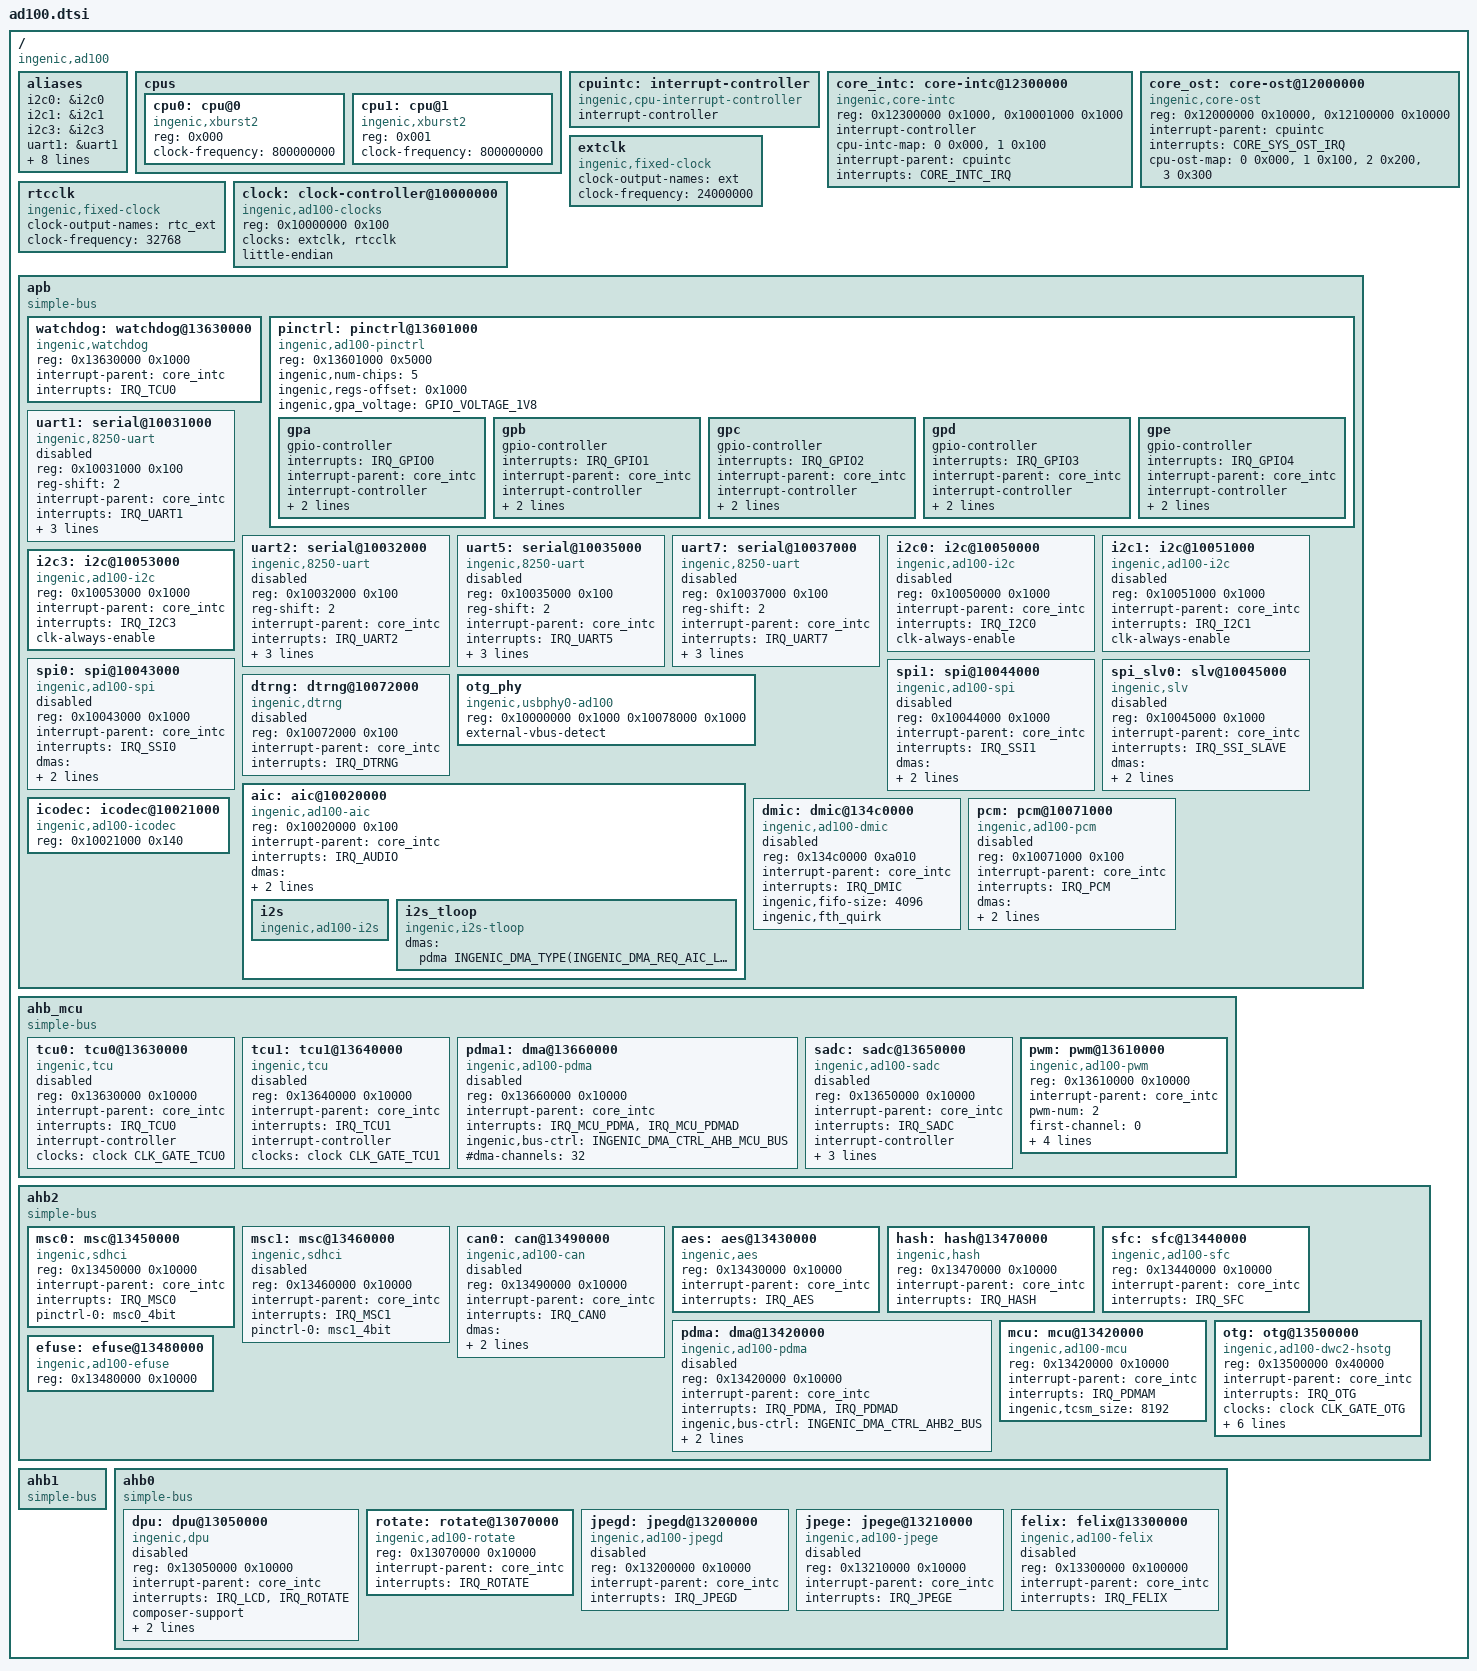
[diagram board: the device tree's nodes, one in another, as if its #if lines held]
#include <dt-bindings/interrupt-controller/ad100-irq.h>
#include <dt-bindings/gpio/ingenic-gpio.h>
#include <dt-bindings/clock/ingenic-tcu.h>
#include <dt-bindings/clock/ingenic-ad100.h>
#include <dt-bindings/sound/ingenic-baic.h>
#include <dt-bindings/gpio/ingenic-gpio.h>
#include <dt-bindings/dma/ingenic-pdma.h>

/ {
	#address-cells = <1>;
	#size-cells = <1>;
	compatible = "ingenic,ad100";

	aliases: aliases {
		i2c0 = &i2c0;
		i2c1 = &i2c1;
		i2c3 = &i2c3;
		uart1 = &uart1;
		uart2 = &uart2;
		uart5 = &uart5;
		uart7 = &uart7;
		mmc0 = &msc0;
		mmc1 = &msc1;
		spi0 = &spi0;
		spi1 = &spi1;
		can0 = &can0;
	};

	cpus: cpus {
		#address-cells = <1>;
		#size-cells = <0>;

		cpu0: cpu@0 {
			device_type = "cpu";
			compatible = "ingenic,xburst2";
			reg = <0x000>;
			clock-frequency = <800000000>;
		};

		cpu1: cpu@1 {
			device_type = "cpu";
			compatible = "ingenic,xburst2";
			reg = <0x001>;
			clock-frequency = <800000000>;
		};
	};

	cpuintc: interrupt-controller {
		#address-cells = <0>;
		#interrupt-cells = <1>;
		interrupt-controller;
		compatible = "ingenic,cpu-interrupt-controller";

	};

	core_intc: core-intc@12300000 {
		compatible = "ingenic,core-intc";
		reg = <0x12300000 0x1000>,
		    <0x10001000 0x1000>;
		interrupt-controller;
		#interrupt-cells = <1>;
		cpu-intc-map = <0 0x000>,
			           <1 0x100>;

		interrupt-parent = <&cpuintc>;
		interrupts = <CORE_INTC_IRQ>;
		interrupt-names ="intc";
	};

	core_ost: core-ost@12000000 {
		compatible = "ingenic,core-ost";
		reg = <0x12000000 0x10000>, /*Global ost*/
		      <0x12100000 0x10000>; /*Core ost*/
		interrupt-parent = <&cpuintc>;
		interrupt-names = "sys_ost";
		interrupts = <CORE_SYS_OST_IRQ>;
		cpu-ost-map = 	<0 0x000>,
			<1 0x100>,
			<2 0x200>,
			<3 0x300>;
	};

	extclk: extclk {
		compatible = "ingenic,fixed-clock";
		clock-output-names ="ext";
		#clock-cells = <0>;
		clock-frequency  = <24000000>;
	};

	rtcclk: rtcclk {
		compatible = "ingenic,fixed-clock";
		clock-output-names ="rtc_ext";
		#clock-cells = <0>;
		clock-frequency = <32768>;
	};

	clock: clock-controller@10000000 {
		compatible = "ingenic,ad100-clocks";
		reg = <0x10000000 0x100>;
		clocks = <&extclk>, <&rtcclk>;
		clock-names = "ext", "rtc_ext";
		#clock-cells = <1>;
		little-endian;
	};

	apb {
		compatible = "simple-bus";
		#address-cells = <1>;
		#size-cells = <1>;
		ranges = <>;
		watchdog: watchdog@13630000 {
				compatible = "ingenic,watchdog";
				reg = <0x13630000 0x1000>;
				interrupt-parent = <&core_intc>;
				interrupts = <IRQ_TCU0>;
				status = "ok";
		};

		pinctrl: pinctrl@13601000 {
			compatible = "ingenic,ad100-pinctrl";
			reg = <0x13601000 0x5000>;
			ingenic,num-chips = <5>;
			ingenic,regs-offset = <0x1000>;
			ingenic,gpa_voltage = <GPIO_VOLTAGE_1V8>;

			gpa: gpa {
				gpio-controller;
				#gpio-cells = <3>;
				#ingenic,pincfg-cells = <3>;
				#ingenic,pinmux-cells = <2>;
				interrupts = <IRQ_GPIO0>;
				interrupt-parent = <&core_intc>;
				interrupt-controller;
				#interrupt-cells = <3>;
				ingenic,pull-gpios-low = <0x55555555>;
				ingenic,pull-gpios-high = <0x55555555>;
			};

			gpb: gpb {
				gpio-controller;
				#gpio-cells = <3>;
				#ingenic,pincfg-cells = <3>;
				#ingenic,pinmux-cells = <2>;
				interrupts = <IRQ_GPIO1>;
				interrupt-parent = <&core_intc>;
				interrupt-controller;
				#interrupt-cells = <3>;
				ingenic,pull-gpios-low = <0x55565555>;
				ingenic,pull-gpios-high = <0x55555555>;
			};

			gpc: gpc {
				gpio-controller;
				#gpio-cells = <3>;
				#ingenic,pincfg-cells = <3>;
				#ingenic,pinmux-cells = <2>;
				interrupts = <IRQ_GPIO2>;
				interrupt-parent = <&core_intc>;
				interrupt-controller;
				#interrupt-cells = <3>;
				ingenic,pull-gpios-low = <0x55555555>;
				ingenic,pull-gpios-high = <0x55555555>;
			};

			gpd: gpd {
				gpio-controller;
				#gpio-cells = <3>;
				#ingenic,pincfg-cells = <3>;
				#ingenic,pinmux-cells = <2>;
				interrupts = <IRQ_GPIO3>;
				interrupt-parent = <&core_intc>;
				interrupt-controller;
				#interrupt-cells = <3>;
				ingenic,pull-gpios-low = <0x55555555>;
				ingenic,pull-gpios-high = <0x55555555>;
			};

			gpe: gpe {
				gpio-controller;
				#gpio-cells = <3>;
				#ingenic,pincfg-cells = <3>;
				#ingenic,pinmux-cells = <2>;
				interrupts = <IRQ_GPIO4>;
				interrupt-parent = <&core_intc>;
				interrupt-controller;
				#interrupt-cells = <3>;
				ingenic,pull-gpios-low = <0x55555555>;
				ingenic,pull-gpios-high = <0x55555555>;
			};

		};

		uart1: serial@10031000 {
			compatible = "ingenic,8250-uart";
			reg = <0x10031000 0x100>;
			reg-shift = <2>;
			interrupt-parent = <&core_intc>;
			interrupts = <IRQ_UART1>;
			status = "disabled";
			dmas = <&pdma INGENIC_DMA_TYPE(INGENIC_DMA_REQ_UART1_TX)>,
				<&pdma INGENIC_DMA_TYPE(INGENIC_DMA_REQ_UART1_RX)>;
			dma-names = "tx", "rx";
		};
		uart2: serial@10032000 {
			compatible = "ingenic,8250-uart";
			reg = <0x10032000 0x100>;
			reg-shift = <2>;
			interrupt-parent = <&core_intc>;
			interrupts = <IRQ_UART2>;
			status = "disabled";
			dmas = <&pdma INGENIC_DMA_TYPE(INGENIC_DMA_REQ_UART2_TX)>,
				<&pdma INGENIC_DMA_TYPE(INGENIC_DMA_REQ_UART2_RX)>;
			dma-names = "tx", "rx";
		};

		uart5: serial@10035000 {
			compatible = "ingenic,8250-uart";
			reg = <0x10035000 0x100>;
			reg-shift = <2>;
			interrupt-parent = <&core_intc>;
			interrupts = <IRQ_UART5>;
			status = "disabled";
			dmas = <&pdma INGENIC_DMA_TYPE(INGENIC_DMA_REQ_UART5_TX)>,
				<&pdma INGENIC_DMA_TYPE(INGENIC_DMA_REQ_UART5_RX)>;
			dma-names = "tx", "rx";
		};

		uart7: serial@10037000 {
			compatible = "ingenic,8250-uart";
			reg = <0x10037000 0x100>;
			reg-shift = <2>;
			interrupt-parent = <&core_intc>;
			interrupts = <IRQ_UART7>;
			status = "disabled";
			dmas = <&pdma INGENIC_DMA_TYPE(INGENIC_DMA_REQ_UART7_TX)>,
				<&pdma INGENIC_DMA_TYPE(INGENIC_DMA_REQ_UART7_RX)>;
			dma-names = "tx", "rx";
		};

		i2c0: i2c@10050000 {
			compatible = "ingenic,ad100-i2c";
			reg = <0x10050000 0x1000>;
			interrupt-parent = <&core_intc>;
			interrupts = <IRQ_I2C0>;
			#address-cells = <1>;
			#size-cells = <0>;
			clk-always-enable;
			status = "disabled";
		};

		i2c1: i2c@10051000 {
			compatible = "ingenic,ad100-i2c";
			reg = <0x10051000 0x1000>;
			interrupt-parent = <&core_intc>;
			interrupts = <IRQ_I2C1>;
			#address-cells = <1>;
			#size-cells = <0>;
			clk-always-enable;
			status = "disabled";
		};

		i2c3: i2c@10053000 {
			compatible = "ingenic,ad100-i2c";
			reg = <0x10053000 0x1000>;
			interrupt-parent = <&core_intc>;
			interrupts = <IRQ_I2C3>;
			#address-cells = <1>;
			#size-cells = <0>;
			clk-always-enable;
			status = "okay";
		};

		spi0: spi@10043000 {
			compatible = "ingenic,ad100-spi";
			reg = <0x10043000 0x1000>;
			interrupt-parent = <&core_intc>;
			interrupts = <IRQ_SSI0>;
			dmas = <&pdma INGENIC_DMA_TYPE(INGENIC_DMA_REQ_SSI0_TX)>,
				   <&pdma INGENIC_DMA_TYPE(INGENIC_DMA_REQ_SSI0_RX)>;
			dma-names = "tx", "rx";
			#address-cells = <1>;
			#size-cells = <0>;
			status = "disable";
		};

		spi1: spi@10044000 {
			compatible = "ingenic,ad100-spi";
			reg = <0x10044000 0x1000>;
			interrupt-parent = <&core_intc>;
			interrupts = <IRQ_SSI1>;
			dmas = <&pdma INGENIC_DMA_TYPE(INGENIC_DMA_REQ_SSI1_TX)>,
				   <&pdma INGENIC_DMA_TYPE(INGENIC_DMA_REQ_SSI1_RX)>;
			dma-names = "tx", "rx";
			#address-cells = <1>;
			#size-cells = <0>;
			status = "disable";
		};

		spi_slv0: slv@10045000 {
			compatible = "ingenic,slv";
			reg = <0x10045000 0x1000>;
			interrupt-parent = <&core_intc>;
			interrupts = <IRQ_SSI_SLAVE>;
			dmas = <&pdma INGENIC_DMA_TYPE(INGENIC_DMA_REQ_SLV0_TX)>,
				   <&pdma INGENIC_DMA_TYPE(INGENIC_DMA_REQ_SLV0_RX)>;
			dma-names = "tx", "rx";
			#address-cells = <1>;
			#size-cells = <0>;
			status = "disable";
		};

		dtrng: dtrng@10072000 {
			compatible = "ingenic,dtrng";
			reg = <0x10072000 0x100>;
			interrupt-parent = <&core_intc>;
			interrupts = <IRQ_DTRNG>;
			status = "disabled";
		};

		otg_phy: otg_phy {
			#address-cells = <1>;
			#size-cells = <1>;
			compatible = "ingenic,usbphy0-ad100";
			reg = <0x10000000 0x1000 0x10078000 0x1000>;
#ifdef CONFIG_USB_DWC2_EXT_VBUS_DETECT
			external-vbus-detect;
#endif
		};

		aic: aic@10020000 {
			compatible = "ingenic,ad100-aic";
			reg = <0x10020000 0x100>;
			interrupt-parent = <&core_intc>;
			interrupts = <IRQ_AUDIO>;
			dmas = <&pdma INGENIC_DMA_TYPE(INGENIC_DMA_REQ_AIC_TX)>,
			       <&pdma INGENIC_DMA_TYPE(INGENIC_DMA_REQ_AIC_RX)>;
			dma-names = "tx", "rx";

			i2s: i2s {
				compatible = "ingenic,ad100-i2s";
				status = "okay";
			};
			i2s_tloop: i2s_tloop {
				compatible = "ingenic,i2s-tloop";
				dmas = <&pdma INGENIC_DMA_TYPE(INGENIC_DMA_REQ_AIC_LOOP_RX)>;
				dma-names = "rx";
				status = "okay";
			};
		};

		icodec: icodec@10021000 {
			compatible = "ingenic,ad100-icodec";
			reg = <0x10021000 0x140>;
			status = "okay";
		};

		dmic: dmic@134c0000 {
			compatible = "ingenic,ad100-dmic";
			reg = <0x134c0000 0xa010>;
			interrupt-parent = <&core_intc>;
			interrupts = <IRQ_DMIC>;
			ingenic,fifo-size = <4096>;
			ingenic,fth_quirk;
			status = "disable";
		};

		pcm: pcm@10071000 {
			compatible = "ingenic,ad100-pcm";
			reg = <0x10071000 0x100>;
			interrupt-parent = <&core_intc>;
			interrupts = <IRQ_PCM>;
			dmas = <&pdma INGENIC_DMA_TYPE(INGENIC_DMA_REQ_PCM_TX)>,
				   <&pdma INGENIC_DMA_TYPE(INGENIC_DMA_REQ_PCM_RX)>;
			dma-names = "tx", "rx";
			status = "disable";
		};

	};

	ahb_mcu {
		compatible = "simple-bus";
		#address-cells = <1>;
		#size-cells = <1>;
		ranges = <>;

		tcu0: tcu0@13630000 {
				compatible = "ingenic,tcu";
				reg = <0x13630000 0x10000>;
				interrupt-parent = <&core_intc>;
				interrupt-names = "tcu_int0";
				interrupts = <IRQ_TCU0>;
				interrupt-controller;
				clocks = <&clock CLK_GATE_TCU0>;
				clock-names = "gate_tcu0";
				status = "disable";
		};
		tcu1: tcu1@13640000 {
				compatible = "ingenic,tcu";
				reg = <0x13640000 0x10000>;
				interrupt-parent = <&core_intc>;
				interrupt-names = "tcu_int1";
				interrupts = <IRQ_TCU1>;
				interrupt-controller;
				clocks = <&clock CLK_GATE_TCU1>;
				clock-names = "gate_tcu1";
				status = "disable";

		};

		pdma1: dma@13660000 {
			compatible = "ingenic,ad100-pdma";
			reg = <0x13660000 0x10000>;
			interrupt-parent = <&core_intc>;
			interrupt-names = "pdma", "pdmad";
			interrupts = <IRQ_MCU_PDMA>, <IRQ_MCU_PDMAD>;
			ingenic,bus-ctrl = <INGENIC_DMA_CTRL_AHB_MCU_BUS>;
			#dma-channels = <32>;
			#dma-cells = <1>;
			status ="disable";
			//ingenic,reserved-chs = <0x3>;
		};
		sadc: sadc@13650000 {
			compatible = "ingenic,ad100-sadc";
			reg = <0x13650000 0x10000>;
			interrupt-parent = <&core_intc>;
			interrupts = <IRQ_SADC>;
			interrupt-controller;
			dmas = <&pdma1 INGENIC_DMA_AHB_MCU_TYPE(INGENIC_DMA_REQ_SADC_SEQ1_RX)>,
			     <&pdma1 INGENIC_DMA_AHB_MCU_TYPE(INGENIC_DMA_REQ_SADC_SEQ2_RX)>;
			dma-names = "seq1rx", "seq2rx";
			status = "disable";
		};

		pwm: pwm@13610000 {
			compatible = "ingenic,ad100-pwm";
			#pwm-cells = <2>;
			reg = <0x13610000 0x10000>;
			interrupt-parent = <&core_intc>;
			pwm-num = <2>;
			first-channel = <0>;
			interrupts = <IRQ_PWM0>;
			dmas = <&pdma1 INGENIC_DMA_AHB_MCU_TYPE(INGENIC_DMA_REQ_PWM8_TX)>,
			        <&pdma1 INGENIC_DMA_AHB_MCU_TYPE(INGENIC_DMA_REQ_PWM9_TX)>;
			dma-names = "8", "9";
		};
	};

	ahb2 {
		compatible = "simple-bus";
		#address-cells = <1>;
		#size-cells = <1>;
		ranges = <>;

		msc0: msc@13450000 {
			compatible = "ingenic,sdhci";
			reg = <0x13450000 0x10000>;
			interrupt-parent = <&core_intc>;
			interrupts = <IRQ_MSC0>;
			pinctrl-names ="default", "default";
			pinctrl-0 = <&msc0_4bit>;
		};

		msc1: msc@13460000 {
			compatible = "ingenic,sdhci";
			reg = <0x13460000 0x10000>;
			status = "disabled";
			interrupt-parent = <&core_intc>;
			interrupts = <IRQ_MSC1>;
			pinctrl-names ="default";
			pinctrl-0 = <&msc1_4bit>;
		};
		can0: can@13490000 {
			compatible = "ingenic,ad100-can";
			reg = <0x13490000 0x10000>;
			interrupt-parent = <&core_intc>;
			interrupts = <IRQ_CAN0>;
			dmas = <&pdma INGENIC_DMA_TYPE(INGENIC_DMA_REQ_CAN0_TX)>,
				   <&pdma INGENIC_DMA_TYPE(INGENIC_DMA_REQ_CAN0_RX)>;
			dma-names = "tx", "rx";
			#address-cells = <1>;
			#size-cells = <0>;
			status = "disable";
		};

		aes: aes@13430000 {
			compatible = "ingenic,aes";
			reg = <0x13430000 0x10000>;
			interrupt-parent = <&core_intc>;
			interrupts = <IRQ_AES>;
			status = "ok";
		};

		hash: hash@13470000 {
			compatible = "ingenic,hash";
			reg = <0x13470000 0x10000>;
			interrupt-parent = <&core_intc>;
			interrupts = <IRQ_HASH>;
			status = "ok";
		};

		sfc: sfc@13440000 {
			compatible = "ingenic,ad100-sfc";
			reg = <0x13440000 0x10000>;
			interrupt-parent = <&core_intc>;
			interrupts = <IRQ_SFC>;
		};

		pdma: dma@13420000 {
			compatible = "ingenic,ad100-pdma";
			reg = <0x13420000 0x10000>;
			interrupt-parent = <&core_intc>;
			interrupt-names = "pdma", "pdmad";
			interrupts = <IRQ_PDMA>, <IRQ_PDMAD>;
			ingenic,bus-ctrl = <INGENIC_DMA_CTRL_AHB2_BUS>;
			#dma-channels = <32>;
			#dma-cells = <1>;
			ingenic,reserved-chs = <0x3>;
			status ="disable";
		};

		mcu: mcu@13420000 {
			compatible = "ingenic,ad100-mcu";
			reg = <0x13420000 0x10000>;
			interrupt-parent = <&core_intc>;
			interrupt-names = "pdmam";
			interrupts = <IRQ_PDMAM>;
			ingenic,tcsm_size = <8192>;
		};

		otg: otg@13500000 {
			compatible = "ingenic,ad100-dwc2-hsotg";
			reg = <0x13500000 0x40000>;
			interrupt-parent = <&core_intc>;
			interrupts = <IRQ_OTG>;
			clocks = <&clock CLK_GATE_OTG>;
			clock-names = "gate_otg";
			ingenic,usbphy=<&otg_phy>;

			g-rx-fifo-size = <1096>;
			g-np-tx-fifo-size = <512>;
			g-tx-fifo-size = <16 16 16 128 256 256 512 768>;
			status = "okay";
#ifdef CONFIG_USB_DWC2_EXT_ID_PIN
			external-id-pin;
#endif
#ifdef CONFIG_USB_DWC2_FORCE_FULL_SPEED
			force-full-speed;
#endif
		};

		efuse: efuse@13480000 {
			compatible = "ingenic,ad100-efuse";
			reg = <0x13480000 0x10000>;
			status = "okay";
		};

	};

	ahb1 {
		compatible = "simple-bus";
		#address-cells = <1>;
		#size-cells = <1>;
		ranges = <>;

	};

	ahb0 {
		compatible = "simple-bus";
		#address-cells = <1>;
		#size-cells = <1>;
		ranges = <>;

		dpu: dpu@13050000 {
			compatible = "ingenic,dpu";
			reg = <0x13050000 0x10000>;
			interrupt-parent = <&core_intc>;
			interrupts = <IRQ_LCD>,<IRQ_ROTATE>;
			status = "disabled";
			composer-support;
			/* for mipi device*/
			dsi-host-reg = <0x10023000>;
			dsi-phy-reg  = <0x10024000>;
		};

		rotate: rotate@13070000 {
			compatible = "ingenic,ad100-rotate";
			reg = <0x13070000 0x10000>;
			interrupt-parent = <&core_intc>;
			interrupts = <IRQ_ROTATE>;
			status = "okay";
		};

		jpegd: jpegd@13200000 {
			compatible = "ingenic,ad100-jpegd";
			reg = <0x13200000 0x10000>;
			interrupt-parent = <&core_intc>;
			interrupts = <IRQ_JPEGD>;
			status = "disabled";
		};

		jpege: jpege@13210000 {
			compatible = "ingenic,ad100-jpege";
			reg = <0x13210000 0x10000>;
			interrupt-parent = <&core_intc>;
			interrupts = <IRQ_JPEGE>;
			status = "disabled";
		};

		felix: felix@13300000 {
			compatible = "ingenic,ad100-felix";
			reg = <0x13300000 0x100000>;
			interrupt-parent = <&core_intc>;
			interrupts = <IRQ_FELIX>;
			status = "disabled";
		};

	};

};
#include "ad100-pinctrl.dtsi"
